# STM32H750 register map
File version: 2.7
CPU: CM7 r0p1, little endian, MPU, FPU, 4 interrupt priority bits
Registers are 32-bit, read-write, reset 0x0 unless marked. A register's access mark holds for its fields unless they carry their own. Offsets are from the block's base; [hi:lo] are bit positions; {n}, {i} and the like mark numbered series.

## COMP1
Base 0x58003800
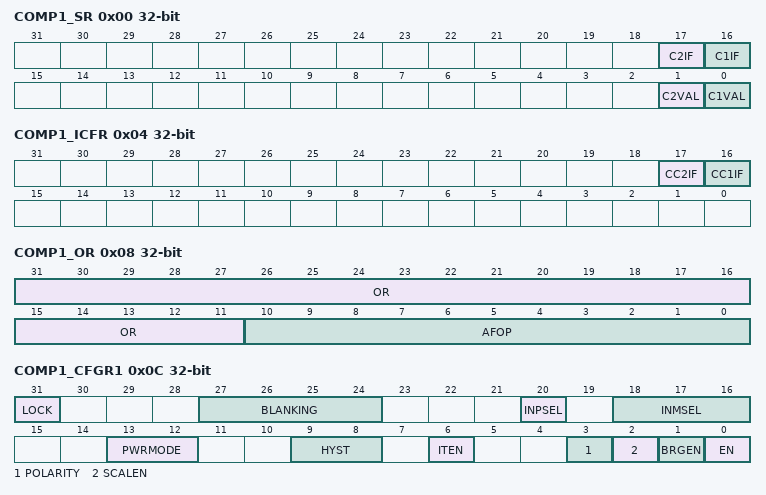
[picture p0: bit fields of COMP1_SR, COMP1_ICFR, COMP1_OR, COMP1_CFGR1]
0x00 COMP1_SR ro — Comparator status register
  [17] C2IF — COMP channel 2 Interrupt Flag
  [16] C1IF — COMP channel 1 Interrupt Flag
  [1] C2VAL — COMP channel 2 output status bit
  [0] C1VAL — COMP channel 1 output status bit
0x04 COMP1_ICFR wo — Comparator interrupt clear flag register
  [17] CC2IF — Clear COMP channel 2 Interrupt Flag
  [16] CC1IF — Clear COMP channel 1 Interrupt Flag
0x08 COMP1_OR — Comparator option register
  [31:11] OR — Option Register
  [10:0] AFOP — Selection of source for alternate function of output ports
0x0C COMP1_CFGR1 — Comparator configuration register 1
  [31] LOCK — Lock bit
  [27:24] BLANKING — COMP channel 1 blanking source selection bits
  [20] INPSEL — COMP channel 1 non-inverting input selection bit
  [18:16] INMSEL — COMP channel 1 inverting input selection field
  [13:12] PWRMODE — Power Mode of the COMP channel 1
  [9:8] HYST — COMP channel 1 hysteresis selection bits
  [6] ITEN — COMP channel 1 interrupt enable
  [3] POLARITY — COMP channel 1 polarity selection bit
  [2] SCALEN — Voltage scaler enable bit
  [1] BRGEN — Scaler bridge enable
  [0] EN — COMP channel 1 enable bit
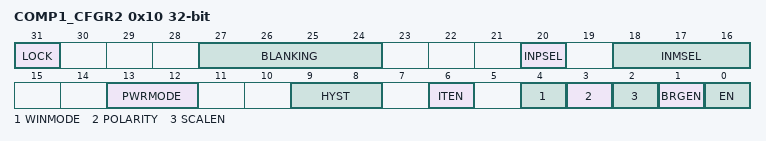
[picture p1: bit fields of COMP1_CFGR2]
0x10 COMP1_CFGR2 — Comparator configuration register 2
  [31] LOCK — Lock bit
  [27:24] BLANKING — COMP channel 1 blanking source selection bits
  [20] INPSEL — COMP channel 1 non-inverting input selection bit
  [18:16] INMSEL — COMP channel 1 inverting input selection field
  [13:12] PWRMODE — Power Mode of the COMP channel 1
  [9:8] HYST — COMP channel 1 hysteresis selection bits
  [6] ITEN — COMP channel 1 interrupt enable
  [4] WINMODE — Window comparator mode selection bit
  [3] POLARITY — COMP channel 1 polarity selection bit
  [2] SCALEN — Voltage scaler enable bit
  [1] BRGEN — Scaler bridge enable
  [0] EN — COMP channel 1 enable bit

## DMAMUX1 — DMAMUX
Base 0x40020800
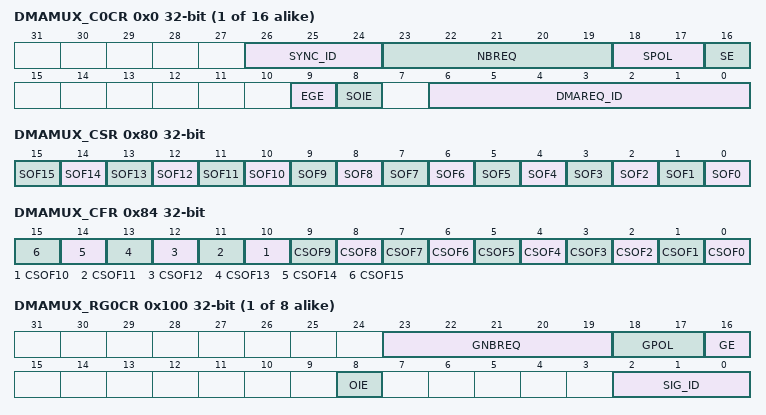
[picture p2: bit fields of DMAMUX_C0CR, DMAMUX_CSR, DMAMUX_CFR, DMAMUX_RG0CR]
{0x0+4i} DMAMUX_C{i}CR (i=0..15)
  [26:24] SYNC_ID — Synchronization identification Selects the synchronization input (see inputs to resources).
  [23:19] NBREQ — Number of DMA requests minus 1 to forward Defines the number of DMA requests to forward to the DMA controller after a synchronization event, and/or the number of DMA requests before an output event is generated. This field shall only be written when both SE and EGE bits are low.
  [18:17] SPOL — Synchronization polarity Defines the edge polarity of the selected synchronization input:
    0=No event, i.e. no synchronization nor detection.; 1=Rising edge; 2=Falling edge; 3=Rising and falling edges
  [16] SE — Synchronization enable
    0=Synchronization disabled; 1=Synchronization enabled
  [9] EGE — Event generation enable
    0=Event generation disabled; 1=Event generation enabled
  [8] SOIE — Synchronization overrun interrupt enable
    0=Interrupt disabled; 1=Interrupt enabled
  [6:0] DMAREQ_ID — DMA request identification Selects the input DMA request. See the DMAMUX table about assignments of multiplexer inputs to resources.
0x80 DMAMUX_CSR ro
  [n] SOF{n} (n=0..15) — Synchronization overrun event flag The flag is set when a synchronization event occurs on a DMA request line multiplexer channel x, while the DMA request counter value is lower than NBREQ. The flag is cleared by writing 1 to the corresponding CSOFx bit in DMAMUX_CFR register. For DMAMUX2 bits 15:8 are reserved, keep them at reset value.
0x84 DMAMUX_CFR wo
  [n] CSOF{n} (n=0..15) — Clear synchronization overrun event flag Writing 1 in each bit clears the corresponding overrun flag SOFx in the DMAMUX_CSR register.
{0x100+4i} DMAMUX_RG{i}CR (i=0..7)
  [23:19] GNBREQ — Number of DMA requests to be generated (minus 1) Defines the number of DMA requests to be generated after a trigger event. The actual number of generated DMA requests is GNBREQ +1. Note: This field must be written only when GE bit is disabled.
  [18:17] GPOL — DMA request generator trigger polarity Defines the edge polarity of the selected trigger input
    0=No event, i.e. no trigger detection nor generation.; 1=Rising edge; 2=Falling edge; 3=Rising and falling edges
  [16] GE — DMA request generator channel x enable
    0=DMA request generator channel x disabled; 1=DMA request generator channel x enabled
  [8] OIE — Trigger overrun interrupt enable
    0=Interrupt on a trigger overrun event occurrence is disabled; 1=Interrupt on a trigger overrun event occurrence is enabled
  [2:0] SIG_ID — Signal identification Selects the DMA request trigger input used for the channel x of the DMA request generator
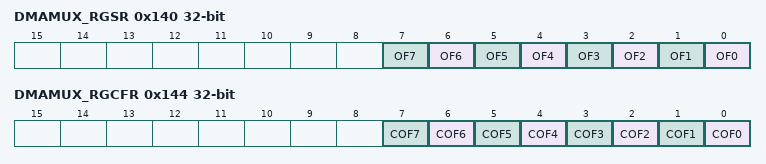
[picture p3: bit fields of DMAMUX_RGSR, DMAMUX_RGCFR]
0x140 DMAMUX_RGSR ro
  [n] OF{n} (n=0..7) — [:0]: Trigger overrun event flag The flag is set when a new trigger event occurs on DMA request generator channel x, before the request counter underrun (the internal request counter programmed via the GNBREQ field of the DMAMUX_RGxCR register). The flag is cleared by writing 1 to the corresponding COFx bit in the DMAMUX_RGCFR register.
0x144 DMAMUX_RGCFR wo
  [n] COF{n} (n=0..7) — Clear trigger overrun event flag Writing 1 in each bit clears the corresponding overrun flag OFx in the DMAMUX_RGSR register.

## Notices in the file
Copyright (c) 2025 STMicroelectronics.
SPDX-License-Identifier: Apache-2.0
Licensed under the Apache License, Version 2.0 (the "License");
you may not use this file except in compliance with the License.
You may obtain a copy of the License at
http://www.apache.org/licenses/LICENSE-2.0
Unless required by applicable law or agreed to in writing, software
distributed under the License is distributed on an "AS IS" BASIS,
WITHOUT WARRANTIES OR CONDITIONS OF ANY KIND, either express or implied.
See the License for the specific language governing permissions and
limitations under the License.
